AUTOSAR XML (schema 323)
package /Cluster
  can cluster CAN
    physical channel CAN
      frame FRAME_DiagResponse: id 0x600, frame-length=8, can-addressing-mode=STANDARD
        pdu PDU_DiagResponse: length=64
      frame FRAME_DiagRequest: id 0x700, frame-length=8, can-addressing-mode=STANDARD
        pdu PDU_DiagRequest: length=64
      frame FRAME_LockingRemoteControlRequest: id 0x1, from SUT_Driver, to SUT, frame-length=1, can-addressing-mode=STANDARD
        pdu PDU_LockingRemoteControlRequest: length=8
          signal LockRequest: start 0, 2 bit, little-endian, data-type=LockRequest, to SUT
      frame FRAME_CentralLockingSystemState: id 0x0, from SUT, frame-length=1, can-addressing-mode=STANDARD
        pdu PDU_CentralLockingSystemState: length=8
          signal AntiTheftSystemActive: start 1, 1 bit, little-endian, data-type=AntiTheftSystemActive
          signal LockState: start 0, 1 bit, little-endian, data-type=LockState
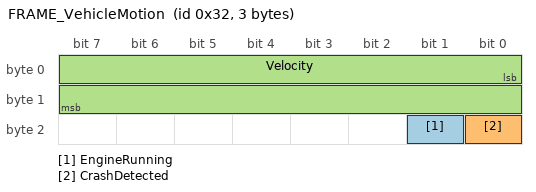
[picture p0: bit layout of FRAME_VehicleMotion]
      frame FRAME_VehicleMotion: id 0x32, from SUT_Driver, to SUT, frame-length=3, can-addressing-mode=STANDARD
        pdu PDU_VehicleMotion: length=24
          signal EngineRunning: start 17, 1 bit, little-endian, data-type=EngineRunning
          signal CrashDetected: start 16, 1 bit, little-endian, data-type=CrashDetected, to SUT
          signal Velocity: start 0, 16 bit, little-endian, data-type=Velocity, to SUT
      frame FRAME_WindowState: id 0x64, from SUT, frame-length=2, can-addressing-mode=STANDARD
        pdu PDU_WindowState: length=16
          signal WindowPosition: start 0, 8 bit, little-endian, data-type=WindowPosition
          signal WindowMotion: start 14, 2 bit, little-endian, data-type=WindowMotion
      frame FRAME_WindowControl: id 0x65, from SUT_Driver, to SUT, frame-length=1, can-addressing-mode=STANDARD
        pdu PDU_WindowControl: length=8
          signal KeyDown: start 1, 1 bit, little-endian, data-type=KeyDown, to SUT
          signal KeyUp: start 0, 1 bit, little-endian, data-type=KeyUp, to SUT
package /DataType
  10 x integer type:
    LockRequest: compu {0=idle, 1=Request_lock, 2=Request_unlock, 3=Comfort_lock, phys=raw}
    AntiTheftSystemActive: compu {0=not_moving, 1=currently_closing, 2=currently_opening, phys=raw+2}
    LockState: compu {0=not_moving, 1=currently_closing, 2=currently_opening, phys=raw*2+3}
    EngineRunning: compu {phys=raw*3}
    CrashDetected: compu {phys=raw}
    Velocity: compu {phys=raw*3}
    WindowPosition: compu {phys=raw}
    WindowMotion: compu {0=not_moving, 1=currently_closing, 2=currently_opening, phys=raw}
    KeyDown: compu {phys=raw}
    KeyUp: compu {phys=raw}
package /DataType/Unit
  10 x unit:
    LockRequest
    AntiTheftSystemActive
    LockState
    EngineRunning
    CrashDetected
    Velocity
    WindowPosition
    WindowMotion
    KeyDown
    KeyUp
package /ECU
  ecu instance SUT_Driver: associated-i-pdu-group=SUT_Driver_Tx
    communication connector CN_SUT_Driver
  ecu instance SUT: associated-i-pdu-group=[SUT_Rx, SUT_Tx]
    communication connector CN_SUT
package /IPDUGroup
  i pdu group SUT_Driver_Tx: communication-direction=OUT, i-pdu=[PDU_LockingRemoteControlRequest, PDU_VehicleMotion, PDU_WindowControl]
  i pdu group SUT_Tx: communication-direction=OUT, i-pdu=[PDU_CentralLockingSystemState, PDU_WindowState]
  i pdu group SUT_Rx: communication-direction=IN, i-pdu=PDU_WindowControl
